# psoc6_01 register map
Vendor: Cypress Semiconductor; Series: PSoC6_01; File version: 1.0
CPU: CM4 r0p1, little endian, MPU, FPU, VTOR, 3 interrupt priority bits
Registers are 32-bit, read-write, reset 0x0 unless marked. A register's access mark holds for its fields unless they carry their own. Offsets are from the block's base; [hi:lo] are bit positions; lines under a group give offsets from that group; {n}, {i} and the like mark numbered series.

## TCPWM0 — Timer/Counter/PWM
Base 0x40380000
Same registers: TCPWM1 0x40390000
0x00 CTRL — TCPWM control register
  [31:0] COUNTER_ENABLED — Counter enables for counters 0 up to CNT_NR-1. '0': counter disabled. '1': counter enabled. Counter static configuration information (e.g. CTRL.MODE, all TR_CTRL0, TR_CTRL1, and TR_CTRL2 register fields) should only be modified when the counter is disabled. When a counter is disabled, command and status information associated to the counter is cleared by HW, this includes: - the associated counter triggers in the CMD register are set to '0'. - the counter's interrupt cause fields in counter's INTR register. - the counter's status fields in counter's STATUS register.. - the counter's trigger outputs ('tr_overflow', 'tr_underflow' and 'tr_compare_match'). - the counter's line outputs ('line_out' and 'line_compl_out'). In multi-core environments, use the CTRL_SET/CTRL_CLR registers to avoid race-conditions on read-modify-write attempts to this register.
0x04 CTRL_CLR — TCPWM control clear register
  [31:0] COUNTER_ENABLED — Alias of CTRL that only allows disabling of counters. A write access: '0': Does nothing. '1': Clears respective COUNTER_ENABLED field. A read access returns CTRL.COUNTER_ENABLED.
0x08 CTRL_SET — TCPWM control set register
  [31:0] COUNTER_ENABLED — Alias of CTRL that only allows enabling of counters. A write access: '0': Does nothing. '1': Sets respective COUNTER_ENABLED field. A read access returns CTRL.COUNTER_ENABLED.
0x0C CMD_CAPTURE — TCPWM capture command register
  [31:0] COUNTER_CAPTURE — Counters SW capture trigger. When written with '1', a capture trigger is generated and the HW sets the field to '0' when the SW trigger has taken effect. It should be noted that the HW operates on the counter frequency. If the counter is disabled through CTRL.COUNTER_ENABLED, the field is immediately set to '0'.
0x10 CMD_RELOAD — TCPWM reload command register
  [31:0] COUNTER_RELOAD — Counters SW reload trigger. For HW behavior, see COUNTER_CAPTURE field.
0x14 CMD_STOP — TCPWM stop command register
  [31:0] COUNTER_STOP — Counters SW stop trigger. For HW behavior, see COUNTER_CAPTURE field.
0x18 CMD_START — TCPWM start command register
  [31:0] COUNTER_START — Counters SW start trigger. For HW behavior, see COUNTER_CAPTURE field.
0x1C INTR_CAUSE ro — TCPWM Counter interrupt cause register
  [31:0] COUNTER_INT — Counters interrupt signal active. If the counter is disabled through CTRL.COUNTER_ENABLED, the associated interrupt field is immediately set to '0'.
{0x100+0x40*i} CNT[{i}] (i=0..23) group — Timer/Counter/PWM Counter Module
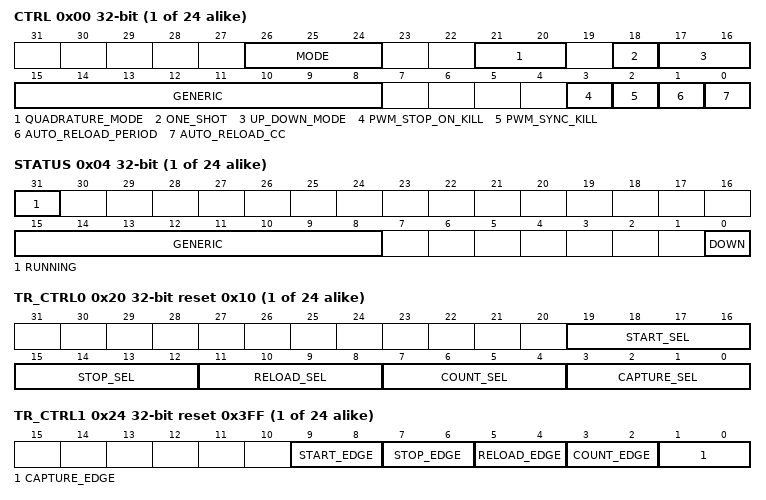
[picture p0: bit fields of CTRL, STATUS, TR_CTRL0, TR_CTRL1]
  0x00 CTRL — Counter control register
    [26:24] MODE — Counter mode.
      0=TIMER (Timer mode); 2=CAPTURE (Capture mode); 3=QUAD (Quadrature encoding mode); 4=PWM (Pulse width modulation (PWM) mode); 5=PWM_DT (PWM with deadtime insertion mode); 6=PWM_PR (Pseudo random pulse width modulation)
    [21:20] QUADRATURE_MODE — In QUAD mode selects quadrature encoding mode (X1/X2/X4). In PWM, PWM_DT and PWM_PR modes, these two bits can be used to invert 'dt_line_out' and 'dt_line_compl_out'. Inversion is the last step in generation of 'dt_line_out' and 'dt_line_compl_out'; i.e. a disabled output line 'dt_line_out' has the value QUADRATURE_MODE[0] and a disabled output line 'dt_line_compl_out' has the value QUADRATURE_MODE[1].
      0=X1 encoding (QUAD mode); 1=X2 (X2 encoding (QUAD mode)); 2=X4 (X4 encoding (QUAD mode))
    [18] ONE_SHOT — When '0', counter runs continuous. When '1', counter is turned off by hardware when a terminal count event is generated.
    [17:16] UP_DOWN_MODE — Determines counter direction.
      0=COUNT_UP (Count up (to PERIOD). An overflow event is generated when the counter changes from a state in which COUNTER equals PERIOD. A terminal count event is generated when the counter changes from a state in which COUNTER equals PERIOD.); 1=COUNT_DOWN (Count down (to '0'). An underflow event is generated when the counter changes from a state in which COUNTER equals '0'. A terminal count event is generated when the counter changes from a state in which COUNTER equals '0'.); 2=COUNT_UPDN1 (Count up (to PERIOD), then count down (to '0'). An overflow event is generated when the counter changes from a state in which COUNTER equals PERIOD. An underflow event is generated when the counter changes from a state in which COUNTER equals '0'. A terminal count event is generated when the counter changes from a state in which COUNTER equals '0'.); 3=COUNT_UPDN2 (Count up (to PERIOD), then count down (to '0'). An overflow event is generated when the counter changes from a state in which COUNTER equals PERIOD. An underflow event is generated when the counter changes from a state in which COUNTER equals '0'. A terminal count event is generated when the counter changes from a state in which COUNTER equals '0' AND when the counter changes from a state in which COUNTER equals PERIOD (this counter direction can be used for PWM functionality with asymmetrical updates).)
    [15:8] GENERIC — Generic 8-bit control field. In PWM_DT mode, this field is used to determine the dead time: amount of dead time cycles in the counter clock domain. In all other modes, the lower 3 bits of this field determine pre-scaling of the selected counter clock.
      0=DIVBY1 (Divide by 1 (other-than-PWM_DT mode)); 1=DIVBY2 (Divide by 2 (other-than-PWM_DT mode)); 2=DIVBY4 (Divide by 4 (other-than-PWM_DT mode)); 3=DIVBY8 (Divide by 8 (other-than-PWM_DT mode)); 4=DIVBY16 (Divide by 16 (other-than-PWM_DT mode)); 5=DIVBY32 (Divide by 32 (other-than-PWM_DT mode)); 6=DIVBY64 (Divide by 64 (other-than-PWM_DT mode)); 7=DIVBY128 (Divide by 128 (other-than-PWM_DT mode))
    [3] PWM_STOP_ON_KILL — Specifies whether the counter stops on a kill events: '0': kill event does NOT stop counter. '1': kill event stops counter. This field has a function in PWM, PWM_DT and PWM_PR modes only.
    [2] PWM_SYNC_KILL — Specifies asynchronous/synchronous kill behavior: '1': synchronous kill mode: the kill event disables the 'dt_line_out' and 'dt_line_compl_out' signals till the next terminal count event (synchronous kill). In synchronous kill mode, STOP_EDGE should be RISING_EDGE. '0': asynchronous kill mode: the kill event only disables the 'dt_line_out' and 'dt_line_compl_out' signals when present. In asynchronous kill mode, STOP_EDGE should be NO_EDGE_DET. This field has a function in PWM and PWM_DT modes only. This field is only used when PWM_STOP_ON_KILL is '0'.
    [1] AUTO_RELOAD_PERIOD — Specifies switching of the PERIOD and buffered PERIOD values. This field has a function in PWM, PWM_DT and PWM_PR modes. '0': never switch. '1': switch on a terminal count event with and actively pending switch event.
    [0] AUTO_RELOAD_CC — Specifies switching of the CC and buffered CC values. This field has a function in TIMER, PWM, PWM_DT and PWM_PR modes. Timer mode: '0': never switch. '1': switch on a compare match event. PWM, PWM_DT, PWM_PR modes: '0: never switch. '1': switch on a terminal count event with an actively pending switch event.
  0x04 STATUS ro — Counter status register
    [31] RUNNING — When '0', the counter is NOT running. When '1', the counter is running.
    [15:8] GENERIC — Generic 8-bit counter field. In PWM_DT mode, this counter is used for dead time insertion. In all other modes, this counter is used for pre-scaling the selected counter clock. PWM_DT mode can NOT use prescaled clock functionality.
    [0] DOWN — When '0', counter is counting up. When '1', counter is counting down. In QUAD mode, this field indicates the direction of the latest counter change: '0' when last incremented and '1' when last decremented.
  0x08 COUNTER — Counter count register
    [31:0] COUNTER — 16-bit / 32-bit counter value. It is advised to not write to this field when the counter is running.
  0x0C CC reset 0xFFFFFFFF — Counter compare/capture register
    [31:0] CC — In CAPTURE mode, captures the counter value. In other modes, compared to counter value.
  0x10 CC_BUFF reset 0xFFFFFFFF — Counter buffered compare/capture register
    [31:0] CC — Additional buffer for counter CC register.
  0x14 PERIOD reset 0xFFFFFFFF — Counter period register
    [31:0] PERIOD — Period value: upper value of the counter. When the counter should count for n cycles, this field should be set to n-1.
  0x18 PERIOD_BUFF reset 0xFFFFFFFF — Counter buffered period register
    [31:0] PERIOD — Additional buffer for counter PERIOD register.
  0x20 TR_CTRL0 reset 0x10 — Counter trigger control register 0
    [19:16] START_SEL — Selects one of the 16 input triggers as a start trigger. In QUAD mode, this is the second phase (phi B).
    [15:12] STOP_SEL — Selects one of the 16 input triggers as a stop trigger. In PWM, PWM_DT and PWM_PR modes, this is the kill trigger. In these modes, the kill trigger is used to either temporarily block the PWM outputs (PWM_STOP_ON_KILL is '0') or stop the functionality (PWM_STOP_ON_KILL is '1'). For the PWM and PWM_DT modes, the blocking of the output signals can be asynchronous (STOP_EDGE should be NO_EDGE_DET) in which case the blocking is as long as the trigger is '1' or synchronous (STOP_EDGE should be RISING_EDGE) in which case it extends till the next terminal count event.
    [11:8] RELOAD_SEL — Selects one of the 16 input triggers as a reload trigger. In QUAD mode, this is the index or revolution pulse. In this mode, it will update the counter with 0x8000 (counter midpoint).
    [7:4] COUNT_SEL — Selects one of the 16 input triggers as a count trigger. In QUAD mode, this is the first phase (phi A). Default setting selects input trigger 1, which is always '1'.
    [3:0] CAPTURE_SEL — Selects one of the 16 input triggers as a capture trigger. Input trigger 0 is always '0' and input trigger is always '1'. In the PWM, PWM_DT and PWM_PR modes this trigger is used to switch the values if the compare and period registers with their buffer counterparts.
  0x24 TR_CTRL1 reset 0x3FF — Counter trigger control register 1
    [all] fields
      0=RISING_EDGE (Rising edge. Any rising edge generates an event.); 1=FALLING_EDGE (Falling edge. Any falling edge generates an event.); 2=BOTH_EDGES (Rising AND falling edge. Any odd amount of edges generates an event.); 3=NO_EDGE_DET (No edge detection, use trigger as is.)
    [9:8] START_EDGE — A start event will start the counter; i.e. the counter will become running. Starting does NOT enable the counter. A start event will not initialize the counter whereas the reload event does.
    [7:6] STOP_EDGE — A stop event, will stop the counter; i.e. it will no longer be running. Stopping will NOT disable the counter.
    [5:4] RELOAD_EDGE — A reload event will initialize the counter. When counting up, the counter is initialized to '0'. When counting down, the counter is initialized with PERIOD.
    [3:2] COUNT_EDGE — A counter event will increase or decrease the counter by '1'.
    [1:0] CAPTURE_EDGE — A capture event will copy the counter value into the CC register.
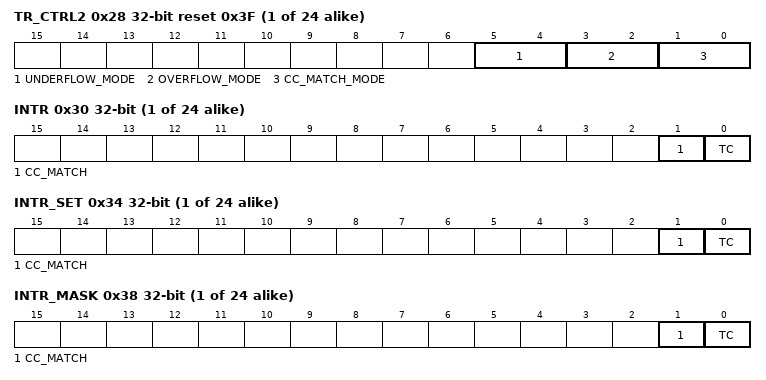
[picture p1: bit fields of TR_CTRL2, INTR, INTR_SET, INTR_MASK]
  0x28 TR_CTRL2 reset 0x3F — Counter trigger control register 2
    [all] fields
      0=SET (Set to '1'); 1=CLEAR (Set to '0'); 2=INVERT; 3=NO_CHANGE
    [5:4] UNDERFLOW_MODE — Determines the effect of a counter underflow event (COUNTER reaches '0') on the 'line_out' output signals.
    [3:2] OVERFLOW_MODE — Determines the effect of a counter overflow event (COUNTER reaches PERIOD) on the 'line_out' output signals.
    [1:0] CC_MATCH_MODE — Determines the effect of a compare match event (COUNTER equals CC register) on the 'line_out' output signals. Note that INVERT is especially useful for center aligned pulse width modulation. To generate a duty cycle of 0 percent, the counter CC register should be set to '0'. For a 100 percent duty cycle, the counter CC register should be set to larger than the counter PERIOD register.
  0x30 INTR — Interrupt request register
    [1] CC_MATCH — Counter matches CC register event. Set to '1', when event is detected. Write with '1' to clear bit.
    [0] TC — Terminal count event. Set to '1', when event is detected. Write with '1' to clear bit.
  0x34 INTR_SET — Interrupt set request register
    [1] CC_MATCH — Write with '1' to set corresponding bit in interrupt request register.
    [0] TC — Write with '1' to set corresponding bit in interrupt request register.
  0x38 INTR_MASK — Interrupt mask register
    [1] CC_MATCH — Mask bit for corresponding bit in interrupt request register.
    [0] TC — Mask bit for corresponding bit in interrupt request register.
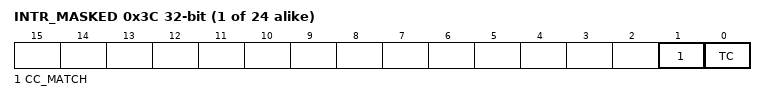
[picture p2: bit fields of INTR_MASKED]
  0x3C INTR_MASKED ro — Interrupt masked request register
    [1] CC_MATCH — Logical and of corresponding request and mask bits.
    [0] TC — Logical and of corresponding request and mask bits.
